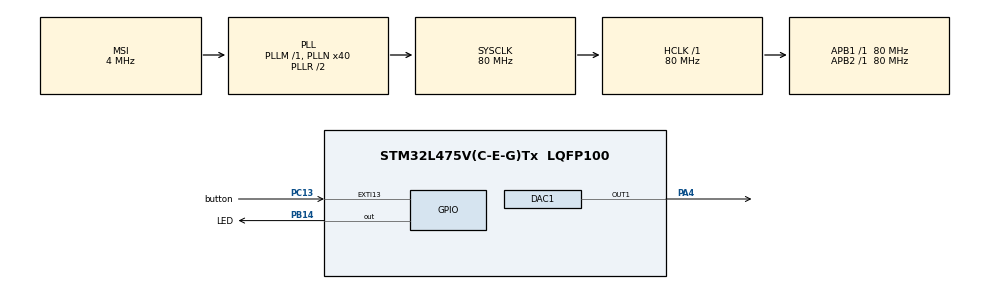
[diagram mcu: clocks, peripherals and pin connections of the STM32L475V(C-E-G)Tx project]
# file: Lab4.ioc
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DAC1.DAC_Trigger-DAC_OUT1=DAC_TRIGGER_T2_TRGO
Dma.DAC_CH1.0.Direction=DMA_MEMORY_TO_PERIPH
Dma.DAC_CH1.0.Instance=DMA1_Channel3
Dma.DAC_CH1.0.MemDataAlignment=DMA_MDATAALIGN_WORD
Dma.DAC_CH1.0.MemInc=DMA_MINC_ENABLE
Dma.DAC_CH1.0.Mode=DMA_CIRCULAR
Dma.DAC_CH1.0.PeriphDataAlignment=DMA_PDATAALIGN_WORD
Dma.DAC_CH1.0.PeriphInc=DMA_PINC_DISABLE
Dma.DAC_CH1.0.Priority=DMA_PRIORITY_LOW
Dma.Request0=DAC_CH1
Mcu.Family=STM32L4
Mcu.Name=STM32L475V(C-E-G)Tx
Mcu.Package=LQFP100
NVIC.DMA1_Channel3_IRQn=true\:0\:0\:false\:false\:true\:false\:true
NVIC.EXTI15_10_IRQn=true\:0\:0\:false\:false\:true\:true\:true
NVIC.PriorityGroup=NVIC_PRIORITYGROUP_4
NVIC.TIM2_IRQn=true\:0\:0\:false\:false\:true\:true\:true
NVIC.TIM6_DAC_IRQn=true\:0\:0\:false\:false\:true\:true\:true
PA4.Signal=COMP_DAC11_group
PB14.GPIO_Label=LED
PB14.Signal=GPIO_Output
PC13.GPIO_Label=button
PC13.Signal=GPXTI13
ProjectManager.HeapSize=0x200
ProjectManager.StackSize=0x400
ProjectManager.TargetToolchain=STM32CubeIDE
RCC.ADCFreq_Value=48000000
RCC.AHBFreq_Value=80000000
RCC.APB1Freq_Value=80000000
RCC.APB1TimFreq_Value=80000000
RCC.APB2Freq_Value=80000000
RCC.APB2TimFreq_Value=80000000
RCC.CortexFreq_Value=80000000
RCC.HCLKFreq_Value=80000000
RCC.HSE_VALUE=8000000
RCC.HSI_VALUE=16000000
RCC.MSI_VALUE=4000000
RCC.PLLN=40
RCC.PLLSAI1N=24
RCC.SYSCLKFreq_VALUE=80000000
RCC.SYSCLKSource=RCC_SYSCLKSOURCE_PLLCLK
RCC.USBFreq_Value=48000000
RCC.VCOOutputFreq_Value=160000000
SH.COMP_DAC11_group.0=DAC1_OUT1,DAC_OUT1
TIM2.Period=1800
TIM2.TIM_MasterOutputTrigger=TIM_TRGO_UPDATE
VP_TIM2_VS_ClockSourceINT.Mode=Internal
board=B-L475E-IOT01A1

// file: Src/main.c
/* USER CODE BEGIN Header */
/**
 ******************************************************************************
 * @file           : main.c
 * @brief          : Main program body
 ******************************************************************************
 * @attention
 *
 * <h2><center>&copy; Copyright (c) 2020 STMicroelectronics.
 * All rights reserved.</center></h2>
 *
 * This software component is licensed by ST under BSD 3-Clause license,
 * the "License"; You may not use this file except in compliance with the
 * License. You may obtain a copy of the License at:
 *                        opensource.org/licenses/BSD-3-Clause
 *Shaluo WU
 ******************************************************************************
 */
/* USER CODE END Header */
#include "main.h"

/* USER CODE BEGIN Includes */
#define ARM_MATH_CM4
#include "arm_math.h"

/* USER CODE END Includes */

DAC_HandleTypeDef hdac1;
DMA_HandleTypeDef hdma_dac_ch1;

TIM_HandleTypeDef htim2;

void SystemClock_Config(void);
static void MX_GPIO_Init(void);
static void MX_DMA_Init(void);
static void MX_TIM2_Init(void);
static void MX_DAC1_Init(void);

/* USER CODE BEGIN 0 */
int counter = 0;
int pb = 1;
uint8_t c6[44];
uint8_t e6[34];
uint8_t g6[28];
/* USER CODE END 0 */

int main(void) {

	/* MCU Configuration--------------------------------------------------------*/

	/* Reset of all peripherals, Initializes the Flash interface and the Systick. */
	HAL_Init();

	/* Configure the system clock */
	SystemClock_Config();

	/* Initialize all configured peripherals */
	MX_GPIO_Init();
	MX_DMA_Init();
	MX_TIM2_Init();
	MX_DAC1_Init();
	/* USER CODE BEGIN 2 */
	//	HAL_DAC_Start(&hdac1, DAC_CHANNEL_1);
	HAL_DAC_Start_DMA(&hdac1, DAC_CHANNEL_1, c6, 44, DAC_ALIGN_8B_R);

	for (float i = 0; i < 44; i++) {
		c6[(uint8_t) i] = (uint8_t) (arm_sin_f32(PI * i / 22) + 1) * 2048
				* 0.33;
	}

	for (float i = 0; i < 34; i++) {
		e6[(uint8_t) i] = (uint8_t) (arm_sin_f32(PI * i / 17) + 1) * 2048
				* 0.33;
	}

	for (float i = 0; i < 28; i++) {
		g6[(uint8_t) i] = (uint8_t) (arm_sin_f32(PI * i / 14) + 1) * 2048
				* 0.33;
	}

	HAL_TIM_Base_Start_IT(&htim2);

	/* USER CODE END 2 */

	/* Infinite loop */
	while (1) {

	}
}

void SystemClock_Config(void) {
	RCC_OscInitTypeDef RCC_OscInitStruct = { 0 };
	RCC_ClkInitTypeDef RCC_ClkInitStruct = { 0 };

	/** Initializes the RCC Oscillators according to the specified parameters
	 * in the RCC_OscInitTypeDef structure.
	 */
	RCC_OscInitStruct.OscillatorType = RCC_OSCILLATORTYPE_MSI;
	RCC_OscInitStruct.MSIState = RCC_MSI_ON;
	RCC_OscInitStruct.MSICalibrationValue = 0;
	RCC_OscInitStruct.MSIClockRange = RCC_MSIRANGE_6;
	RCC_OscInitStruct.PLL.PLLState = RCC_PLL_ON;
	RCC_OscInitStruct.PLL.PLLSource = RCC_PLLSOURCE_MSI;
	RCC_OscInitStruct.PLL.PLLM = 1;
	RCC_OscInitStruct.PLL.PLLN = 40;
	RCC_OscInitStruct.PLL.PLLP = RCC_PLLP_DIV7;
	RCC_OscInitStruct.PLL.PLLQ = RCC_PLLQ_DIV2;
	RCC_OscInitStruct.PLL.PLLR = RCC_PLLR_DIV2;
	if (HAL_RCC_OscConfig(&RCC_OscInitStruct) != HAL_OK) {
		Error_Handler();
	}
	/** Initializes the CPU, AHB and APB buses clocks
	 */
	RCC_ClkInitStruct.ClockType = RCC_CLOCKTYPE_HCLK | RCC_CLOCKTYPE_SYSCLK
			| RCC_CLOCKTYPE_PCLK1 | RCC_CLOCKTYPE_PCLK2;
	RCC_ClkInitStruct.SYSCLKSource = RCC_SYSCLKSOURCE_PLLCLK;
	RCC_ClkInitStruct.AHBCLKDivider = RCC_SYSCLK_DIV1;
	RCC_ClkInitStruct.APB1CLKDivider = RCC_HCLK_DIV1;
	RCC_ClkInitStruct.APB2CLKDivider = RCC_HCLK_DIV1;

	if (HAL_RCC_ClockConfig(&RCC_ClkInitStruct, FLASH_LATENCY_4) != HAL_OK) {
		Error_Handler();
	}
	/** Configure the main internal regulator output voltage
	 */
	if (HAL_PWREx_ControlVoltageScaling(PWR_REGULATOR_VOLTAGE_SCALE1)
			!= HAL_OK) {
		Error_Handler();
	}
}

static void MX_DAC1_Init(void) {

	DAC_ChannelConfTypeDef sConfig = { 0 };

	/** DAC Initialization
	 */
	hdac1.Instance = DAC1;
	if (HAL_DAC_Init(&hdac1) != HAL_OK) {
		Error_Handler();
	}
	/** DAC channel OUT1 config
	 */
	sConfig.DAC_SampleAndHold = DAC_SAMPLEANDHOLD_DISABLE;
	sConfig.DAC_Trigger = DAC_TRIGGER_T2_TRGO;
	sConfig.DAC_OutputBuffer = DAC_OUTPUTBUFFER_ENABLE;
	sConfig.DAC_ConnectOnChipPeripheral = DAC_CHIPCONNECT_DISABLE;
	sConfig.DAC_UserTrimming = DAC_TRIMMING_FACTORY;
	if (HAL_DAC_ConfigChannel(&hdac1, &sConfig, DAC_CHANNEL_1) != HAL_OK) {
		Error_Handler();
	}

}

static void MX_TIM2_Init(void) {

	TIM_ClockConfigTypeDef sClockSourceConfig = { 0 };
	TIM_MasterConfigTypeDef sMasterConfig = { 0 };

	htim2.Instance = TIM2;
	htim2.Init.Prescaler = 0;
	htim2.Init.CounterMode = TIM_COUNTERMODE_UP;
	htim2.Init.Period = 1800;
	htim2.Init.ClockDivision = TIM_CLOCKDIVISION_DIV1;
	htim2.Init.AutoReloadPreload = TIM_AUTORELOAD_PRELOAD_DISABLE;
	if (HAL_TIM_Base_Init(&htim2) != HAL_OK) {
		Error_Handler();
	}
	sClockSourceConfig.ClockSource = TIM_CLOCKSOURCE_INTERNAL;
	if (HAL_TIM_ConfigClockSource(&htim2, &sClockSourceConfig) != HAL_OK) {
		Error_Handler();
	}
	sMasterConfig.MasterOutputTrigger = TIM_TRGO_UPDATE;
	sMasterConfig.MasterSlaveMode = TIM_MASTERSLAVEMODE_DISABLE;
	if (HAL_TIMEx_MasterConfigSynchronization(&htim2, &sMasterConfig)
			!= HAL_OK) {
		Error_Handler();
	}

}

static void MX_DMA_Init(void) {

	/* DMA controller clock enable */
	__HAL_RCC_DMA1_CLK_ENABLE();

	/* DMA interrupt init */
	/* DMA1_Channel3_IRQn interrupt configuration */
	HAL_NVIC_SetPriority(DMA1_Channel3_IRQn, 0, 0);
	HAL_NVIC_EnableIRQ(DMA1_Channel3_IRQn);

}

static void MX_GPIO_Init(void) {
	GPIO_InitTypeDef GPIO_InitStruct = { 0 };

	/* GPIO Ports Clock Enable */
	__HAL_RCC_GPIOC_CLK_ENABLE();
	__HAL_RCC_GPIOA_CLK_ENABLE();
	__HAL_RCC_GPIOB_CLK_ENABLE();

	/*Configure GPIO pin Output Level */
	HAL_GPIO_WritePin(LED_GPIO_Port, LED_Pin, GPIO_PIN_RESET);

	/*Configure GPIO pin : button_Pin */
	GPIO_InitStruct.Pin = button_Pin;
	GPIO_InitStruct.Mode = GPIO_MODE_IT_RISING;
	GPIO_InitStruct.Pull = GPIO_NOPULL;
	HAL_GPIO_Init(button_GPIO_Port, &GPIO_InitStruct);

	/*Configure GPIO pin : LED_Pin */
	GPIO_InitStruct.Pin = LED_Pin;
	GPIO_InitStruct.Mode = GPIO_MODE_OUTPUT_PP;
	GPIO_InitStruct.Pull = GPIO_NOPULL;
	GPIO_InitStruct.Speed = GPIO_SPEED_FREQ_LOW;
	HAL_GPIO_Init(LED_GPIO_Port, &GPIO_InitStruct);

	/* EXTI interrupt init*/
	HAL_NVIC_SetPriority(EXTI15_10_IRQn, 0, 0);
	HAL_NVIC_EnableIRQ(EXTI15_10_IRQn);

}

/* USER CODE BEGIN 4 */
void HAL_GPIO_EXTI_Callback(uint16_t GPIO_Pin) {

	if (GPIO_Pin == button_Pin) {
		HAL_GPIO_TogglePin(GPIOB, LED_Pin);
		HAL_DAC_Stop_DMA(&hdac1, DAC_CHANNEL_1);

		if (pb == 0) {
			pb = 1;
			HAL_DAC_Start_DMA(&hdac1, DAC_CHANNEL_1, c6, 44, DAC_ALIGN_8B_R);
		} else if (pb == 1) {
			pb = 2;
			HAL_DAC_Start_DMA(&hdac1, DAC_CHANNEL_1, e6, 34, DAC_ALIGN_8B_R);
		} else if (pb == 2) {
			pb = 0;
			HAL_DAC_Start_DMA(&hdac1, DAC_CHANNEL_1, g6, 28, DAC_ALIGN_8B_R);
		}

	}

}
/*
 void HAL_TIM_PeriodElapsedCallback(TIM_HandleTypeDef *htim2) {

 if (counter < 44) {
 counter++;
 } else {
 counter = 0;
 }

 HAL_DAC_SetValue(&hdac1, DAC_CHANNEL_1, DAC_ALIGN_8B_R, c6[counter]);
 }
 */

/* USER CODE END 4 */

void Error_Handler(void) {
}

/************************ (C) COPYRIGHT STMicroelectronics *****END OF FILE****/

/* USER CODE BEGIN Header */
/**
  ******************************************************************************
  * @file           : main.c
  * @brief          : Main program body
  ******************************************************************************
  * @attention
  *
  * <h2><center>&copy; Copyright (c) 2020 STMicroelectronics.
  * All rights reserved.</center></h2>
  *
  * This software component is licensed by ST under BSD 3-Clause license,
  * the "License"; You may not use this file except in compliance with the
  * License. You may obtain a copy of the License at:
  *                        opensource.org/licenses/BSD-3-Clause
  *
  ******************************************************************************
  */
/* USER CODE END Header */
#include "main.h"

/* USER CODE BEGIN Includes */
#define ARM_MATH_CH4
#include "arm_math.h"
/* USER CODE END Includes */

DAC_HandleTypeDef hdac1;

TIM_HandleTypeDef htim2;
DMA_HandleTypeDef hdma_tim2_up;

void SystemClock_Config(void);
static void MX_GPIO_Init(void);
static void MX_DMA_Init(void);
static void MX_DAC1_Init(void);
static void MX_TIM2_Init(void);

/* USER CODE BEGIN 0 */
//As the timer frequency is 44.1 kHz,
//choose a sample number of 44,
//set the sine wave frequency to about 1k Hz (within the 1~2 kHz)
#define pi 3.14159265
	uint32_t sine[44];
	int counter = 0;

#define pi 3.1415926
	uint32_t sinx[44];
	uint32_t C6[42];
	uint32_t E6[34];
	uint32_t G6[28];
int pb = 1;
//uint32_t sinx[44];
//uint32_t C6[42];
//uint32_t E6[34];
//uint32_t G6[28];
/*
void createSine(){
	for(int i = 0; i < 44; i++){
		sine[i] = 0.33*(1 + arm_sin_f32(2*pi*i/44))*2048;
	}
}
*/
/* USER CODE END 0 */

int main(void)
{

  /* MCU Configuration--------------------------------------------------------*/

  /* Reset of all peripherals, Initializes the Flash interface and the Systick. */
  HAL_Init();

  /* Configure the system clock */
  SystemClock_Config();

  /* Initialize all configured peripherals */
  MX_GPIO_Init();
  MX_DMA_Init();
  MX_DAC1_Init();
  MX_TIM2_Init();
  /* USER CODE BEGIN 2 */

  /*
  HAL_TIM_Base_Start_IT(&htim2);
  HAL_DAC_Start(&hdac1,DAC_CHANNEL_1);
  //createSine();
  for(int t = 0; t < 44; t++){
	  sine[t] = (arm_sin_f32(2*pi*t/44)+1)*2048*0.3;
  }
*/

  for(int t = 0; t < 44; t++){
	  sinx[t] = (arm_sin_f32(2*pi*t/44)+1)*2048*0.33;
  }

  for(int i = 0; i < 42; i++){
	  C6[i] = 0.33*(1 + arm_sin_f32(2*pi*i/42))*2048;
  }

  for(int i = 0; i < 34; i++){
	  E6[i] = 0.33*(1 + arm_sin_f32(2*pi*i/34))*2048;
  }

  for(int i = 0; i < 28; i++){
  		G6[i] = 0.33*(1 + arm_sin_f32(2*pi*i/28))*2048;
  }

  HAL_TIM_Base_Start_IT(&htim2);

  HAL_DAC_Start_DMA(&hdac1,DAC_CHANNEL_1, sinx , 44 ,DAC_ALIGN_12B_R);

  /* USER CODE END 2 */

  /* Infinite loop */
  while (1)
  {

  }
}

void SystemClock_Config(void)
{
  RCC_OscInitTypeDef RCC_OscInitStruct = {0};
  RCC_ClkInitTypeDef RCC_ClkInitStruct = {0};

  /** Initializes the RCC Oscillators according to the specified parameters
  * in the RCC_OscInitTypeDef structure.
  */
  RCC_OscInitStruct.OscillatorType = RCC_OSCILLATORTYPE_MSI;
  RCC_OscInitStruct.MSIState = RCC_MSI_ON;
  RCC_OscInitStruct.MSICalibrationValue = 0;
  RCC_OscInitStruct.MSIClockRange = RCC_MSIRANGE_6;
  RCC_OscInitStruct.PLL.PLLState = RCC_PLL_ON;
  RCC_OscInitStruct.PLL.PLLSource = RCC_PLLSOURCE_MSI;
  RCC_OscInitStruct.PLL.PLLM = 1;
  RCC_OscInitStruct.PLL.PLLN = 40;
  RCC_OscInitStruct.PLL.PLLP = RCC_PLLP_DIV7;
  RCC_OscInitStruct.PLL.PLLQ = RCC_PLLQ_DIV2;
  RCC_OscInitStruct.PLL.PLLR = RCC_PLLR_DIV2;
  if (HAL_RCC_OscConfig(&RCC_OscInitStruct) != HAL_OK)
  {
    Error_Handler();
  }
  /** Initializes the CPU, AHB and APB buses clocks
  */
  RCC_ClkInitStruct.ClockType = RCC_CLOCKTYPE_HCLK|RCC_CLOCKTYPE_SYSCLK
                              |RCC_CLOCKTYPE_PCLK1|RCC_CLOCKTYPE_PCLK2;
  RCC_ClkInitStruct.SYSCLKSource = RCC_SYSCLKSOURCE_PLLCLK;
  RCC_ClkInitStruct.AHBCLKDivider = RCC_SYSCLK_DIV1;
  RCC_ClkInitStruct.APB1CLKDivider = RCC_HCLK_DIV1;
  RCC_ClkInitStruct.APB2CLKDivider = RCC_HCLK_DIV1;

  if (HAL_RCC_ClockConfig(&RCC_ClkInitStruct, FLASH_LATENCY_4) != HAL_OK)
  {
    Error_Handler();
  }
  /** Configure the main internal regulator output voltage
  */
  if (HAL_PWREx_ControlVoltageScaling(PWR_REGULATOR_VOLTAGE_SCALE1) != HAL_OK)
  {
    Error_Handler();
  }
}

static void MX_DAC1_Init(void)
{

  DAC_ChannelConfTypeDef sConfig = {0};

  /** DAC Initialization
  */
  hdac1.Instance = DAC1;
  if (HAL_DAC_Init(&hdac1) != HAL_OK)
  {
    Error_Handler();
  }
  /** DAC channel OUT1 config
  */
  sConfig.DAC_SampleAndHold = DAC_SAMPLEANDHOLD_DISABLE;
  sConfig.DAC_Trigger = DAC_TRIGGER_T2_TRGO;
  sConfig.DAC_OutputBuffer = DAC_OUTPUTBUFFER_ENABLE;
  sConfig.DAC_ConnectOnChipPeripheral = DAC_CHIPCONNECT_DISABLE;
  sConfig.DAC_UserTrimming = DAC_TRIMMING_FACTORY;
  if (HAL_DAC_ConfigChannel(&hdac1, &sConfig, DAC_CHANNEL_1) != HAL_OK)
  {
    Error_Handler();
  }

}

static void MX_TIM2_Init(void)
{

  TIM_ClockConfigTypeDef sClockSourceConfig = {0};
  TIM_MasterConfigTypeDef sMasterConfig = {0};

  htim2.Instance = TIM2;
  htim2.Init.Prescaler = 0;
  htim2.Init.CounterMode = TIM_COUNTERMODE_UP;
  htim2.Init.Period = 1841;
  htim2.Init.ClockDivision = TIM_CLOCKDIVISION_DIV1;
  htim2.Init.AutoReloadPreload = TIM_AUTORELOAD_PRELOAD_DISABLE;
  if (HAL_TIM_Base_Init(&htim2) != HAL_OK)
  {
    Error_Handler();
  }
  sClockSourceConfig.ClockSource = TIM_CLOCKSOURCE_INTERNAL;
  if (HAL_TIM_ConfigClockSource(&htim2, &sClockSourceConfig) != HAL_OK)
  {
    Error_Handler();
  }
  sMasterConfig.MasterOutputTrigger = TIM_TRGO_UPDATE;
  sMasterConfig.MasterSlaveMode = TIM_MASTERSLAVEMODE_DISABLE;
  if (HAL_TIMEx_MasterConfigSynchronization(&htim2, &sMasterConfig) != HAL_OK)
  {
    Error_Handler();
  }

}

static void MX_DMA_Init(void)
{

  /* DMA controller clock enable */
  __HAL_RCC_DMA1_CLK_ENABLE();

  /* DMA interrupt init */
  /* DMA1_Channel2_IRQn interrupt configuration */
  HAL_NVIC_SetPriority(DMA1_Channel2_IRQn, 0, 0);
  HAL_NVIC_EnableIRQ(DMA1_Channel2_IRQn);

}

static void MX_GPIO_Init(void)
{
  GPIO_InitTypeDef GPIO_InitStruct = {0};

  /* GPIO Ports Clock Enable */
  __HAL_RCC_GPIOC_CLK_ENABLE();
  __HAL_RCC_GPIOA_CLK_ENABLE();
  __HAL_RCC_GPIOB_CLK_ENABLE();

  /*Configure GPIO pin Output Level */
  HAL_GPIO_WritePin(LED_GPIO_Port, LED_Pin, GPIO_PIN_RESET);

  /*Configure GPIO pin : button_Pin */
  GPIO_InitStruct.Pin = button_Pin;
  GPIO_InitStruct.Mode = GPIO_MODE_IT_RISING;
  GPIO_InitStruct.Pull = GPIO_NOPULL;
  HAL_GPIO_Init(button_GPIO_Port, &GPIO_InitStruct);

  /*Configure GPIO pin : LED_Pin */
  GPIO_InitStruct.Pin = LED_Pin;
  GPIO_InitStruct.Mode = GPIO_MODE_OUTPUT_PP;
  GPIO_InitStruct.Pull = GPIO_NOPULL;
  GPIO_InitStruct.Speed = GPIO_SPEED_FREQ_LOW;
  HAL_GPIO_Init(LED_GPIO_Port, &GPIO_InitStruct);

  /* EXTI interrupt init*/
  HAL_NVIC_SetPriority(EXTI15_10_IRQn, 0, 0);
  HAL_NVIC_EnableIRQ(EXTI15_10_IRQn);

}

/* USER CODE BEGIN 4 */
/*
void HAL_GPIO_EXTI_Callback(uint16_t GPIO_PIN){
	  if(GPIO_PIN == GPIO_PIN_13){
		  HAL_GPIO_TogglePin(LED_GPIO_Port, LED_Pin);
	  }
}

void HAL_TIM_PeriodElapsedCallback(TIM_HandleTypeDef *htim){

	if(htim == &htim2){
		if(counter == 44){
			counter = 0;
		}
		//get_sine();
		HAL_DAC_SetValue(&hdac1, DAC_CHANNEL_1, DAC_ALIGN_12B_R, sine[counter]);
		counter++;
	}
}*/

void HAL_GPIO_EXTI_Callback(uint16_t GPIO_PIN){
	if(GPIO_PIN == GPIO_PIN_13){
		if(pb == 0){
			pb = 1;
			HAL_DAC_Stop_DMA(&hdac1, DAC_CHANNEL_1);
			HAL_DAC_Start_DMA(&hdac1, DAC_CHANNEL_1, C6, 42, DAC_ALIGN_12B_R);
		}
		else if(pb == 1){
			pb = 2;
			HAL_DAC_Stop_DMA(&hdac1, DAC_CHANNEL_1);
			HAL_DAC_Start_DMA(&hdac1, DAC_CHANNEL_1, E6, 34, DAC_ALIGN_12B_R);
		}
		else if(pb == 2){
			pb = 0;
			HAL_DAC_Stop_DMA(&hdac1, DAC_CHANNEL_1);
			HAL_DAC_Start_DMA(&hdac1, DAC_CHANNEL_1, G6, 28, DAC_ALIGN_12B_R);
		}
	}
}

/* USER CODE END 4 */

void Error_Handler(void)
{
}

/************************ (C) COPYRIGHT STMicroelectronics *****END OF FILE****/
